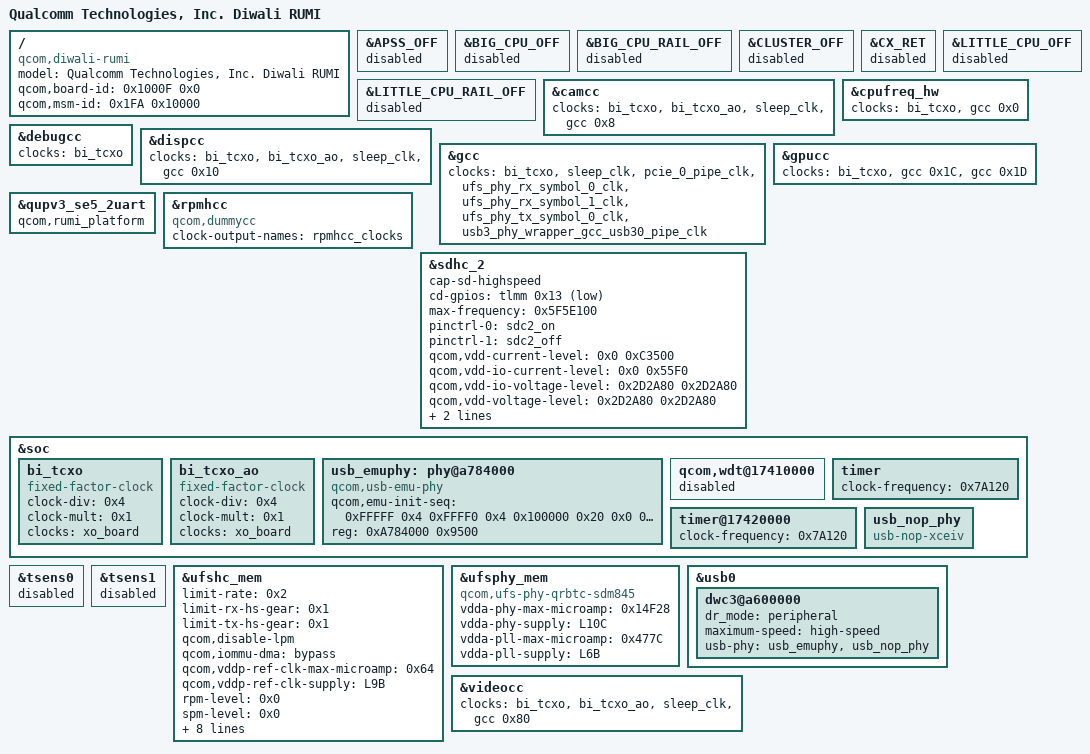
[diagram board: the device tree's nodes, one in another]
/dts-v1/;
// version: 17
// last_comp_version: 16
// boot_cpuid_phys: 0x0

/ {
    compatible = "qcom,diwali-rumi", "qcom,diwali", "qcom,rumi";
    model = "Qualcomm Technologies, Inc. Diwali RUMI";
    qcom,board-id = <0x1000F 0x0>;
    qcom,msm-id = <0x1FA 0x10000>;
};

&APSS_OFF {
    status = "nok";
};

&BIG_CPU_OFF {
    status = "nok";
};

&BIG_CPU_RAIL_OFF {
    status = "nok";
};

&CLUSTER_OFF {
    status = "nok";
};

&CX_RET {
    status = "nok";
};

&LITTLE_CPU_OFF {
    status = "nok";
};

&LITTLE_CPU_RAIL_OFF {
    status = "nok";
};

&camcc {
    clocks = <&bi_tcxo &bi_tcxo_ao &sleep_clk &gcc 0x8>;
};

&cpufreq_hw {
    clocks = <&bi_tcxo &gcc 0x0>;
};

&debugcc {
    clocks = <&bi_tcxo>;
};

&dispcc {
    clocks = <&bi_tcxo &bi_tcxo_ao &sleep_clk &gcc 0x10>;
};

&gcc {
    clocks = <&bi_tcxo &sleep_clk &pcie_0_pipe_clk &ufs_phy_rx_symbol_0_clk &ufs_phy_rx_symbol_1_clk &ufs_phy_tx_symbol_0_clk &usb3_phy_wrapper_gcc_usb30_pipe_clk>;
};

&gpucc {
    clocks = <&bi_tcxo &gcc 0x1C &gcc 0x1D>;
};

&qupv3_se5_2uart {
    qcom,rumi_platform;
};

&rpmhcc {
    clock-output-names = "rpmhcc_clocks";
    compatible = "qcom,dummycc";
};

&sdhc_2 {
    cap-sd-highspeed;
    cd-gpios = <&tlmm 0x13 0x1>;
    max-frequency = <0x5F5E100>;
    pinctrl-0 = <&sdc2_on>;
    pinctrl-1 = <&sdc2_off>;
    pinctrl-names = "default", "sleep";
    qcom,vdd-current-level = <0x0 0xC3500>;
    qcom,vdd-io-current-level = <0x0 0x55F0>;
    qcom,vdd-io-voltage-level = <0x2D2A80 0x2D2A80>;
    qcom,vdd-voltage-level = <0x2D2A80 0x2D2A80>;
    status = "ok";
    vdd-io-supply = <&L6C>;
    vdd-supply = <&L9C>;
};

&soc {
    bi_tcxo: bi_tcxo {
        #clock-cells = <0x0>;
        clock-div = <0x4>;
        clock-mult = <0x1>;
        clocks = <&xo_board>;
        compatible = "fixed-factor-clock";
    };
    bi_tcxo_ao: bi_tcxo_ao {
        #clock-cells = <0x0>;
        clock-div = <0x4>;
        clock-mult = <0x1>;
        clocks = <&xo_board>;
        compatible = "fixed-factor-clock";
    };
    usb_emuphy: phy@a784000 {
        compatible = "qcom,usb-emu-phy";
        qcom,emu-init-seq = <0xFFFFF 0x4 0xFFFF0 0x4 0x100000 0x20 0x0 0x20 0x101F0 0x20 0x100000 0x3C 0x0 0x3C 0x0 0x4>;
        reg = <0xA784000 0x9500>;
    };
    qcom,wdt@17410000 {
        status = "disabled";
    };
    timer {
        clock-frequency = <0x7A120>;
    };
    timer@17420000 {
        clock-frequency = <0x7A120>;
    };
    usb_nop_phy: usb_nop_phy {
        compatible = "usb-nop-xceiv";
    };
};

&tsens0 {
    status = "disabled";
};

&tsens1 {
    status = "disabled";
};

&ufshc_mem {
    limit-rate = <0x2>;
    limit-rx-hs-gear = <0x1>;
    limit-tx-hs-gear = <0x1>;
    qcom,disable-lpm;
    qcom,iommu-dma = "bypass";
    qcom,vddp-ref-clk-max-microamp = <0x64>;
    qcom,vddp-ref-clk-supply = <&L9B>;
    rpm-level = <0x0>;
    spm-level = <0x0>;
    status = "ok";
    vcc-max-microamp = <0xC3500>;
    vcc-supply = <&L7B>;
    vccq-max-microamp = <0xB71B0>;
    vccq-supply = <&L9B>;
    vccq2-max-microamp = <0xB71B0>;
    vccq2-supply = <&L19B>;
    vdd-hba-fixed-regulator;
    vdd-hba-supply = <&gcc_ufs_phy_gdsc>;
};

&ufsphy_mem {
    compatible = "qcom,ufs-phy-qrbtc-sdm845";
    status = "ok";
    vdda-phy-max-microamp = <0x14F28>;
    vdda-phy-supply = <&L10C>;
    vdda-pll-max-microamp = <0x477C>;
    vdda-pll-supply = <&L6B>;
};

&usb0 {
    dwc3@a600000 {
        dr_mode = "peripheral";
        maximum-speed = "high-speed";
        usb-phy = <&usb_emuphy &usb_nop_phy>;
    };
};

&videocc {
    clocks = <&bi_tcxo &bi_tcxo_ao &sleep_clk &gcc 0x80>;
};

